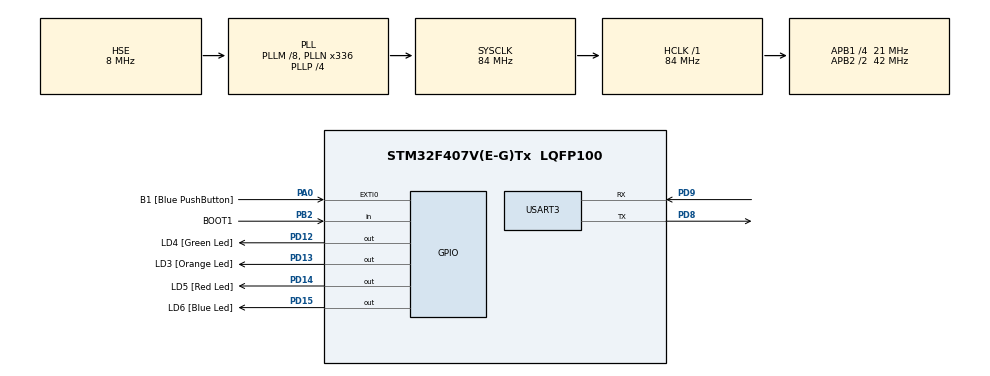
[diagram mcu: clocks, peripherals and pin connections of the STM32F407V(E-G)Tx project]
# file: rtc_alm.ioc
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IWDG.Prescaler=IWDG_PRESCALER_4
Mcu.Family=STM32F4
Mcu.Name=STM32F407V(E-G)Tx
Mcu.Package=LQFP100
NVIC.PriorityGroup=NVIC_PRIORITYGROUP_0
NVIC.RTC_WKUP_IRQn=true\:0\:0\:false\:false\:true\:true\:true
NVIC.USART3_IRQn=true\:0\:0\:false\:false\:true\:true\:true
PA0-WKUP.GPIO_Label=B1 [Blue PushButton]
PA0-WKUP.GPIO_ModeDefaultEXTI=GPIO_MODE_EVT_RISING
PA0-WKUP.GPIO_PuPd=GPIO_NOPULL
PA0-WKUP.Signal=GPXTI0
PA13.GPIO_Label=SWDIO
PA13.Mode=Serial_Wire
PA13.Signal=SYS_JTMS-SWDIO
PA14.GPIO_Label=SWCLK
PA14.Mode=Serial_Wire
PA14.Signal=SYS_JTCK-SWCLK
PB2.GPIO_Label=BOOT1
PB2.GPIO_Mode=GPIO_MODE_INPUT
PB2.GPIO_PuPd=GPIO_NOPULL
PB2.Signal=GPIO_Input
PB3.GPIO_Label=SWO
PB3.Signal=SYS_JTDO-SWO
PC14-OSC32_IN.GPIO_Label=PC14-OSC32_IN
PC14-OSC32_IN.Mode=LSE-External-Oscillator
PC14-OSC32_IN.Signal=RCC_OSC32_IN
PC15-OSC32_OUT.GPIO_Label=PC15-OSC32_OUT
PC15-OSC32_OUT.Mode=LSE-External-Oscillator
PC15-OSC32_OUT.Signal=RCC_OSC32_OUT
PD12.GPIO_Label=LD4 [Green Led]
PD12.GPIO_PuPd=GPIO_NOPULL
PD12.GPIO_Speed=GPIO_SPEED_FREQ_LOW
PD12.Signal=GPIO_Output
PD13.GPIO_Label=LD3 [Orange Led]
PD13.GPIO_PuPd=GPIO_NOPULL
PD13.GPIO_Speed=GPIO_SPEED_FREQ_LOW
PD13.Signal=GPIO_Output
PD14.GPIO_Label=LD5 [Red Led]
PD14.GPIO_PuPd=GPIO_NOPULL
PD14.GPIO_Speed=GPIO_SPEED_FREQ_LOW
PD14.Signal=GPIO_Output
PD15.GPIO_Label=LD6 [Blue Led]
PD15.GPIO_PuPd=GPIO_NOPULL
PD15.GPIO_Speed=GPIO_SPEED_FREQ_LOW
PD15.Signal=GPIO_Output
PD8.Mode=Asynchronous
PD8.Signal=USART3_TX
PD9.Mode=Asynchronous
PD9.Signal=USART3_RX
PH0-OSC_IN.GPIO_Label=PH0-OSC_IN
PH0-OSC_IN.Mode=HSE-External-Oscillator
PH0-OSC_IN.Signal=RCC_OSC_IN
PH1-OSC_OUT.GPIO_Label=PH1-OSC_OUT
PH1-OSC_OUT.Mode=HSE-External-Oscillator
PH1-OSC_OUT.Signal=RCC_OSC_OUT
ProjectManager.HeapSize=0x200
ProjectManager.StackSize=0x400
ProjectManager.TargetToolchain=STM32CubeIDE
RCC.48MHZClocksFreq_Value=48000000
RCC.AHBFreq_Value=84000000
RCC.APB1CLKDivider=RCC_HCLK_DIV4
RCC.APB1Freq_Value=21000000
RCC.APB1TimFreq_Value=42000000
RCC.APB2CLKDivider=RCC_HCLK_DIV2
RCC.APB2Freq_Value=42000000
RCC.APB2TimFreq_Value=84000000
RCC.CortexFreq_Value=84000000
RCC.HCLKFreq_Value=84000000
RCC.HSE_VALUE=8000000
RCC.HSI_VALUE=16000000
RCC.PLLM=8
RCC.PLLN=336
RCC.PLLP=RCC_PLLP_DIV4
RCC.PLLQ=7
RCC.PLLSourceVirtual=RCC_PLLSOURCE_HSE
RCC.RCC_RTC_Clock_Source=RCC_RTCCLKSOURCE_LSI
RCC.RCC_RTC_Clock_SourceVirtual=RCC_RTCCLKSOURCE_LSE
RCC.SYSCLKFreq_VALUE=84000000
RCC.SYSCLKSource=RCC_SYSCLKSOURCE_PLLCLK
RCC.VCOOutputFreq_Value=336000000
RTC.Date=24
RTC.Format=RTC_FORMAT_BIN
RTC.HourFormat=RTC_HOURFORMAT_24
RTC.Month=RTC_MONTH_JULY
RTC.WakeUpClock=RTC_WAKEUPCLOCK_CK_SPRE_16BITS
RTC.WakeUpCounter=20
RTC.WeekDay=RTC_WEEKDAY_FRIDAY
USART3.VirtualMode=VM_ASYNC
VP_IWDG_VS_IWDG.Mode=IWDG_Activate
VP_RTC_VS_RTC_Activate.Mode=RTC_Enabled
VP_RTC_VS_RTC_Calendar.Mode=RTC_Calendar
VP_RTC_VS_RTC_WakeUp_intern.Mode=WakeUp
board=STM32F407G-DISC1

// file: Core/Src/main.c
/* USER CODE BEGIN Header */
/**
  ******************************************************************************
  * @file           : main.c
  * @brief          : Main program body
  ******************************************************************************
  * @attention
  *
  * <h2><center>&copy; Copyright (c) 2020 STMicroelectronics.
  * All rights reserved.</center></h2>
  *
  * This software component is licensed by ST under Ultimate Liberty license
  * SLA0044, the "License"; You may not use this file except in compliance with
  * the License. You may obtain a copy of the License at:
  *                             www.st.com/SLA0044
  *
  ******************************************************************************
  */
/* USER CODE END Header */
#include "main.h"

IWDG_HandleTypeDef hiwdg;

RTC_HandleTypeDef hrtc;

UART_HandleTypeDef huart3;

void SystemClock_Config(void);
static void MX_GPIO_Init(void);
static void MX_RTC_Init(void);
static void MX_USART3_UART_Init(void);
static void MX_IWDG_Init(void);

int main(void)
{

  /* MCU Configuration--------------------------------------------------------*/

  /* Reset of all peripherals, Initializes the Flash interface and the Systick. */
  HAL_Init();

  /* Configure the system clock */
  SystemClock_Config();

  /* Initialize all configured peripherals */
  MX_GPIO_Init();
  MX_RTC_Init();
  MX_USART3_UART_Init();
  MX_IWDG_Init();
  //HAL_GPIO_TogglePin(GPIOD, GPIO_PIN_13) ;
  //HAL_Delay(1000) ;
  /* Infinite loop */
  while (1)
  {
	  HAL_IWDG_Refresh(&hiwdg) ;
	  HAL_Delay(800) ;
  }
}

void SystemClock_Config(void)
{
  RCC_OscInitTypeDef RCC_OscInitStruct = {0};
  RCC_ClkInitTypeDef RCC_ClkInitStruct = {0};
  RCC_PeriphCLKInitTypeDef PeriphClkInitStruct = {0};

  /** Configure the main internal regulator output voltage
  */
  __HAL_RCC_PWR_CLK_ENABLE();
  __HAL_PWR_VOLTAGESCALING_CONFIG(PWR_REGULATOR_VOLTAGE_SCALE1);
  /** Initializes the RCC Oscillators according to the specified parameters
  * in the RCC_OscInitTypeDef structure.
  */
  RCC_OscInitStruct.OscillatorType = RCC_OSCILLATORTYPE_LSI|RCC_OSCILLATORTYPE_HSE;
  RCC_OscInitStruct.HSEState = RCC_HSE_ON;
  RCC_OscInitStruct.LSIState = RCC_LSI_ON;
  RCC_OscInitStruct.PLL.PLLState = RCC_PLL_ON;
  RCC_OscInitStruct.PLL.PLLSource = RCC_PLLSOURCE_HSE;
  RCC_OscInitStruct.PLL.PLLM = 8;
  RCC_OscInitStruct.PLL.PLLN = 336;
  RCC_OscInitStruct.PLL.PLLP = RCC_PLLP_DIV4;
  RCC_OscInitStruct.PLL.PLLQ = 7;
  if (HAL_RCC_OscConfig(&RCC_OscInitStruct) != HAL_OK)
  {
    Error_Handler();
  }
  /** Initializes the CPU, AHB and APB buses clocks
  */
  RCC_ClkInitStruct.ClockType = RCC_CLOCKTYPE_HCLK|RCC_CLOCKTYPE_SYSCLK
                              |RCC_CLOCKTYPE_PCLK1|RCC_CLOCKTYPE_PCLK2;
  RCC_ClkInitStruct.SYSCLKSource = RCC_SYSCLKSOURCE_PLLCLK;
  RCC_ClkInitStruct.AHBCLKDivider = RCC_SYSCLK_DIV1;
  RCC_ClkInitStruct.APB1CLKDivider = RCC_HCLK_DIV4;
  RCC_ClkInitStruct.APB2CLKDivider = RCC_HCLK_DIV2;

  if (HAL_RCC_ClockConfig(&RCC_ClkInitStruct, FLASH_LATENCY_2) != HAL_OK)
  {
    Error_Handler();
  }
  PeriphClkInitStruct.PeriphClockSelection = RCC_PERIPHCLK_RTC;
  PeriphClkInitStruct.RTCClockSelection = RCC_RTCCLKSOURCE_LSI;
  if (HAL_RCCEx_PeriphCLKConfig(&PeriphClkInitStruct) != HAL_OK)
  {
    Error_Handler();
  }
}

static void MX_IWDG_Init(void)
{

  hiwdg.Instance = IWDG;
  hiwdg.Init.Prescaler = IWDG_PRESCALER_16;
  hiwdg.Init.Reload = 2000;  // 1sec
  if (HAL_IWDG_Init(&hiwdg) != HAL_OK)
  {
    Error_Handler();
  }

}

static void MX_RTC_Init(void)
{

  RTC_TimeTypeDef sTime = {0};
  RTC_DateTypeDef sDate = {0};

  /** Initialize RTC Only
  */
  hrtc.Instance = RTC;
  hrtc.Init.HourFormat = RTC_HOURFORMAT_24;
  hrtc.Init.AsynchPrediv = 127;
  hrtc.Init.SynchPrediv = 255;
  hrtc.Init.OutPut = RTC_OUTPUT_DISABLE;
  hrtc.Init.OutPutPolarity = RTC_OUTPUT_POLARITY_HIGH;
  hrtc.Init.OutPutType = RTC_OUTPUT_TYPE_OPENDRAIN;
  if (HAL_RTC_Init(&hrtc) != HAL_OK)
  {
    Error_Handler();
  }

  /** Initialize RTC and set the Time and Date
  */
  sTime.Hours = 0;
  sTime.Minutes = 0;
  sTime.Seconds = 0;
  sTime.DayLightSaving = RTC_DAYLIGHTSAVING_NONE;
  sTime.StoreOperation = RTC_STOREOPERATION_RESET;
  if (HAL_RTC_SetTime(&hrtc, &sTime, RTC_FORMAT_BIN) != HAL_OK)
  {
    Error_Handler();
  }
  sDate.WeekDay = RTC_WEEKDAY_FRIDAY;
  sDate.Month = RTC_MONTH_JULY;
  sDate.Date = 24;
  sDate.Year = 0;

  if (HAL_RTC_SetDate(&hrtc, &sDate, RTC_FORMAT_BIN) != HAL_OK)
  {
    Error_Handler();
  }
  /** Enable the WakeUp

  if (HAL_RTCEx_SetWakeUpTimer_IT(&hrtc, 20, RTC_WAKEUPCLOCK_CK_SPRE_16BITS) != HAL_OK)
  {
    Error_Handler();
  }

}

static void MX_USART3_UART_Init(void)
{

  huart3.Instance = USART3;
  huart3.Init.BaudRate = 115200;
  huart3.Init.WordLength = UART_WORDLENGTH_8B;
  huart3.Init.StopBits = UART_STOPBITS_1;
  huart3.Init.Parity = UART_PARITY_NONE;
  huart3.Init.Mode = UART_MODE_TX_RX;
  huart3.Init.HwFlowCtl = UART_HWCONTROL_NONE;
  huart3.Init.OverSampling = UART_OVERSAMPLING_16;
  if (HAL_UART_Init(&huart3) != HAL_OK)
  {
    Error_Handler();
  }
  /* USER CODE BEGIN USART3_Init 2 */
  HAL_UART_Transmit(&huart3, "UART Init\n\r", 15, 10) ;
  /* USER CODE END USART3_Init 2 */

}

static void MX_GPIO_Init(void)
{
  GPIO_InitTypeDef GPIO_InitStruct = {0};

  /* GPIO Ports Clock Enable */
  __HAL_RCC_GPIOC_CLK_ENABLE();
  __HAL_RCC_GPIOH_CLK_ENABLE();
  __HAL_RCC_GPIOA_CLK_ENABLE();
  __HAL_RCC_GPIOB_CLK_ENABLE();
  __HAL_RCC_GPIOD_CLK_ENABLE();

  /*Configure GPIO pin Output Level */
  HAL_GPIO_WritePin(GPIOD, LD4_Pin|LD3_Pin|LD5_Pin|LD6_Pin, GPIO_PIN_RESET);

  /*Configure GPIO pin : B1_Pin */
  GPIO_InitStruct.Pin = B1_Pin;
  GPIO_InitStruct.Mode = GPIO_MODE_EVT_RISING;
  GPIO_InitStruct.Pull = GPIO_NOPULL;
  HAL_GPIO_Init(B1_GPIO_Port, &GPIO_InitStruct);

  /*Configure GPIO pin : BOOT1_Pin */
  GPIO_InitStruct.Pin = BOOT1_Pin;
  GPIO_InitStruct.Mode = GPIO_MODE_INPUT;
  GPIO_InitStruct.Pull = GPIO_NOPULL;
  HAL_GPIO_Init(BOOT1_GPIO_Port, &GPIO_InitStruct);

  /*Configure GPIO pins : LD4_Pin LD3_Pin LD5_Pin LD6_Pin */
  GPIO_InitStruct.Pin = LD4_Pin|LD3_Pin|LD5_Pin|LD6_Pin;
  GPIO_InitStruct.Mode = GPIO_MODE_OUTPUT_PP;
  GPIO_InitStruct.Pull = GPIO_NOPULL;
  GPIO_InitStruct.Speed = GPIO_SPEED_FREQ_LOW;
  HAL_GPIO_Init(GPIOD, &GPIO_InitStruct);

}

void Error_Handler(void)
{
}

/************************ (C) COPYRIGHT STMicroelectronics *****END OF FILE****/
